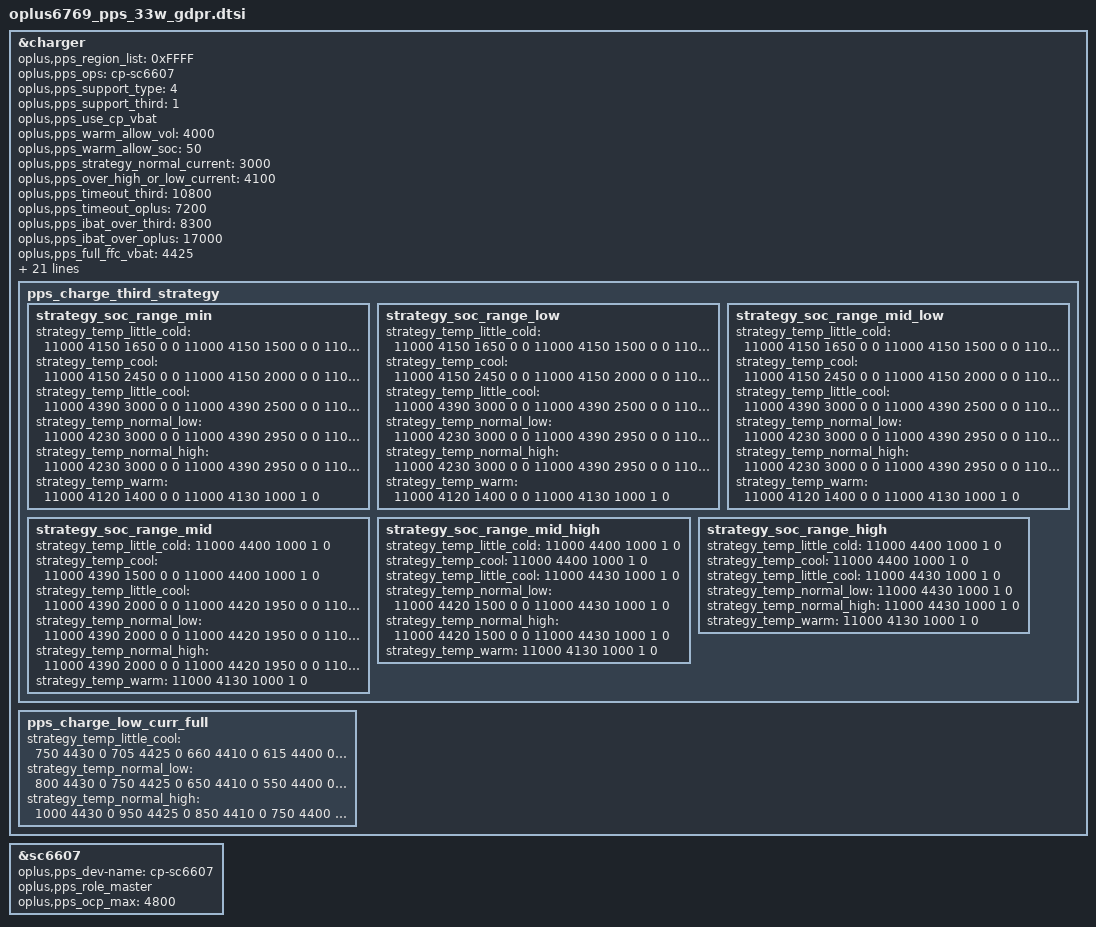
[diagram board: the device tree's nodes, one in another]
&charger {
	oplus,pps_region_list = <0xFFFF>;
	oplus,pps_ops = "cp-sc6607";
	oplus,pps_support_type = <4>;
	oplus,pps_support_third = <1>;
	oplus,pps_use_cp_vbat;
	oplus,pps_warm_allow_vol = <4000>;
	oplus,pps_warm_allow_soc = <50>;
	oplus,pps_strategy_normal_current = <3000>;//3A
	oplus,pps_over_high_or_low_current = <4100>;
	oplus,pps_timeout_third = <10800>;
	oplus,pps_timeout_oplus = <7200>;
	oplus,pps_ibat_over_third = <8300>;
	oplus,pps_ibat_over_oplus = <17000>;
	oplus,pps_full_ffc_vbat = <4425>;
	oplus,pps_full_cool_sw_vbat = <4430>;
	oplus,pps_full_normal_sw_vbat = <4430>;
	oplus,pps_full_normal_hw_vbat = <4440>;
	oplus,pps_full_warm_vbat = <4130>;
	oplus,pps_full_cool_sw_vbat_third = <4430>;
	oplus,pps_full_normal_sw_vbat_third = <4430>;
	oplus,pps_full_normal_hw_vbat_third = <4440>;
	oplus,pps_r_default = <120 10 10 15 15 15 15>;
	oplus,pps_rmos_mohm = <4>;
	oplus,pps_exit_ms = <500>;
	oplus,pps_r_limit = <280 200 140 90 50>;
	oplus,pps_strategy_batt_high_temp = <385 395 420 375 385 410>;
	oplus,pps_strategy_high_current = <3000 3000 2000 3000 3000 3000>;
	oplus,pps_charge_strategy_soc = <0 15 35 50 75 85 90>;
	oplus,pps_charge_strategy_temp = <0 50 120 160 350 430 530>;
	oplus,pps_low_curr_full_strategy_temp = <120 160 350 430>;

	pps_charge_third_strategy {
		// 0 ~ 15
		strategy_soc_range_min {
			strategy_temp_little_cold =	<11000 4150 1650 0 0
							11000 4150 1500 0 0
							11000 4390 1150 0 0
							11000 4400 1000 1 0>;
			strategy_temp_cool =		<11000 4150 2450 0 0
							11000 4150 2000 0 0
							11000 4390 1650 0 0
							11000 4390 1500 0 0
							11000 4400 1000 1 0>;
			strategy_temp_little_cool =	<11000 4390 3000 0 0
							11000 4390 2500 0 0
							11000 4390 2000 0 0
							11000 4420 1950 0 0
							11000 4420 1500 0 0
							11000 4430 1000 1 0>;
			strategy_temp_normal_low =	<11000 4230 3000 0 0
							11000 4390 2950 0 0
							11000 4390 2500 0 0
							11000 4390 2000 0 0
							11000 4420 1950 0 0
							11000 4420 1500 0 0
							11000 4430 1000 1 0>;
			strategy_temp_normal_high =	<11000 4230 3000 0 0
							11000 4390 2950 0 0
							11000 4390 2500 0 0
							11000 4390 2000 0 0
							11000 4420 1950 0 0
							11000 4420 1500 0 0
							11000 4430 1000 1 0>;
			strategy_temp_warm =		<11000 4120 1400 0 0
							11000 4130 1000 1 0>;
		};
		// 15 ~ 35
		strategy_soc_range_low {
			strategy_temp_little_cold =	<11000 4150 1650 0 0
							11000 4150 1500 0 0
							11000 4390 1150 0 0
							11000 4400 1000 1 0>;
			strategy_temp_cool =		<11000 4150 2450 0 0
							11000 4150 2000 0 0
							11000 4390 1650 0 0
							11000 4390 1500 0 0
							11000 4400 1000 1 0>;
			strategy_temp_little_cool =	<11000 4390 3000 0 0
							11000 4390 2500 0 0
							11000 4390 2000 0 0
							11000 4420 1950 0 0
							11000 4420 1500 0 0
							11000 4430 1000 1 0>;
			strategy_temp_normal_low =	<11000 4230 3000 0 0
							11000 4390 2950 0 0
							11000 4390 2500 0 0
							11000 4390 2000 0 0
							11000 4420 1950 0 0
							11000 4420 1500 0 0
							11000 4430 1000 1 0>;
			strategy_temp_normal_high =	<11000 4230 3000 0 0
							11000 4390 2950 0 0
							11000 4390 2500 0 0
							11000 4390 2000 0 0
							11000 4420 1950 0 0
							11000 4420 1500 0 0
							11000 4430 1000 1 0>;
			strategy_temp_warm =		<11000 4120 1400 0 0
							11000 4130 1000 1 0>;
		};
		// 35 ~ 50
		strategy_soc_range_mid_low {
			strategy_temp_little_cold =	<11000 4150 1650 0 0
							11000 4150 1500 0 0
							11000 4390 1150 0 0
							11000 4400 1000 1 0>;
			strategy_temp_cool =		<11000 4150 2450 0 0
							11000 4150 2000 0 0
							11000 4390 1650 0 0
							11000 4390 1500 0 0
							11000 4400 1000 1 0>;
			strategy_temp_little_cool =	<11000 4390 3000 0 0
							11000 4390 2500 0 0
							11000 4390 2000 0 0
							11000 4420 1950 0 0
							11000 4420 1500 0 0
							11000 4430 1000 1 0>;
			strategy_temp_normal_low =	<11000 4230 3000 0 0
							11000 4390 2950 0 0
							11000 4390 2500 0 0
							11000 4390 2000 0 0
							11000 4420 1950 0 0
							11000 4420 1500 0 0
							11000 4430 1000 1 0>;
			strategy_temp_normal_high =	<11000 4230 3000 0 0
							11000 4390 2950 0 0
							11000 4390 2500 0 0
							11000 4390 2000 0 0
							11000 4420 1950 0 0
							11000 4420 1500 0 0
							11000 4430 1000 1 0>;
			strategy_temp_warm =		<11000 4120 1400 0 0
							11000 4130 1000 1 0>;
		};
		// 50 ~ 75
		strategy_soc_range_mid {
			strategy_temp_little_cold =	<11000 4400 1000 1 0>;
			strategy_temp_cool =		<11000 4390 1500 0 0
							11000 4400 1000 1 0>;
			strategy_temp_little_cool =	<11000 4390 2000 0 0
							11000 4420 1950 0 0
							11000 4420 1500 0 0
							11000 4430 1000 1 0>;
			strategy_temp_normal_low =	<11000 4390 2000 0 0
							11000 4420 1950 0 0
							11000 4420 1500 0 0
							11000 4430 1000 1 0>;
			strategy_temp_normal_high =	<11000 4390 2000 0 0
							11000 4420 1950 0 0
							11000 4420 1500 0 0
							11000 4430 1000 1 0>;
			strategy_temp_warm =		<11000 4130 1000 1 0>;
		};
		// 75 ~ 85
		strategy_soc_range_mid_high {
			strategy_temp_little_cold =	<11000 4400 1000 1 0>;
			strategy_temp_cool =		<11000 4400 1000 1 0>;
			strategy_temp_little_cool =	<11000 4430 1000 1 0>;
			strategy_temp_normal_low =	<11000 4420 1500 0 0
							11000 4430 1000 1 0>;
			strategy_temp_normal_high =	<11000 4420 1500 0 0
							11000 4430 1000 1 0>;
			strategy_temp_warm =		<11000 4130 1000 1 0>;
		};
		// 85 ~ 90
		strategy_soc_range_high {
			strategy_temp_little_cold =	<11000 4400 1000 1 0>;
			strategy_temp_cool =		<11000 4400 1000 1 0>;
			strategy_temp_little_cool =	<11000 4430 1000 1 0>;
			strategy_temp_normal_low =	<11000 4430 1000 1 0>;
			strategy_temp_normal_high =	<11000 4430 1000 1 0>;
			strategy_temp_warm =		<11000 4130 1000 1 0>;
		};
	};

	pps_charge_low_curr_full {
		strategy_temp_little_cool = 	<750 4430 0
						705 4425 0
						660 4410 0
						615 4400 0
						570 4390 1>;
		strategy_temp_normal_low =	<800 4430 0
						750 4425 0
						650 4410 0
						550 4400 0
						400 4390 1>;
		strategy_temp_normal_high = 	<1000 4430 0
						950 4425 0
						850 4410 0
						750 4400 0
						600 4390 1>;
	};
};
&sc6607 {
		oplus,pps_dev-name = "cp-sc6607";
		oplus,pps_role_master;
		oplus,pps_ocp_max = <4800>;
};
